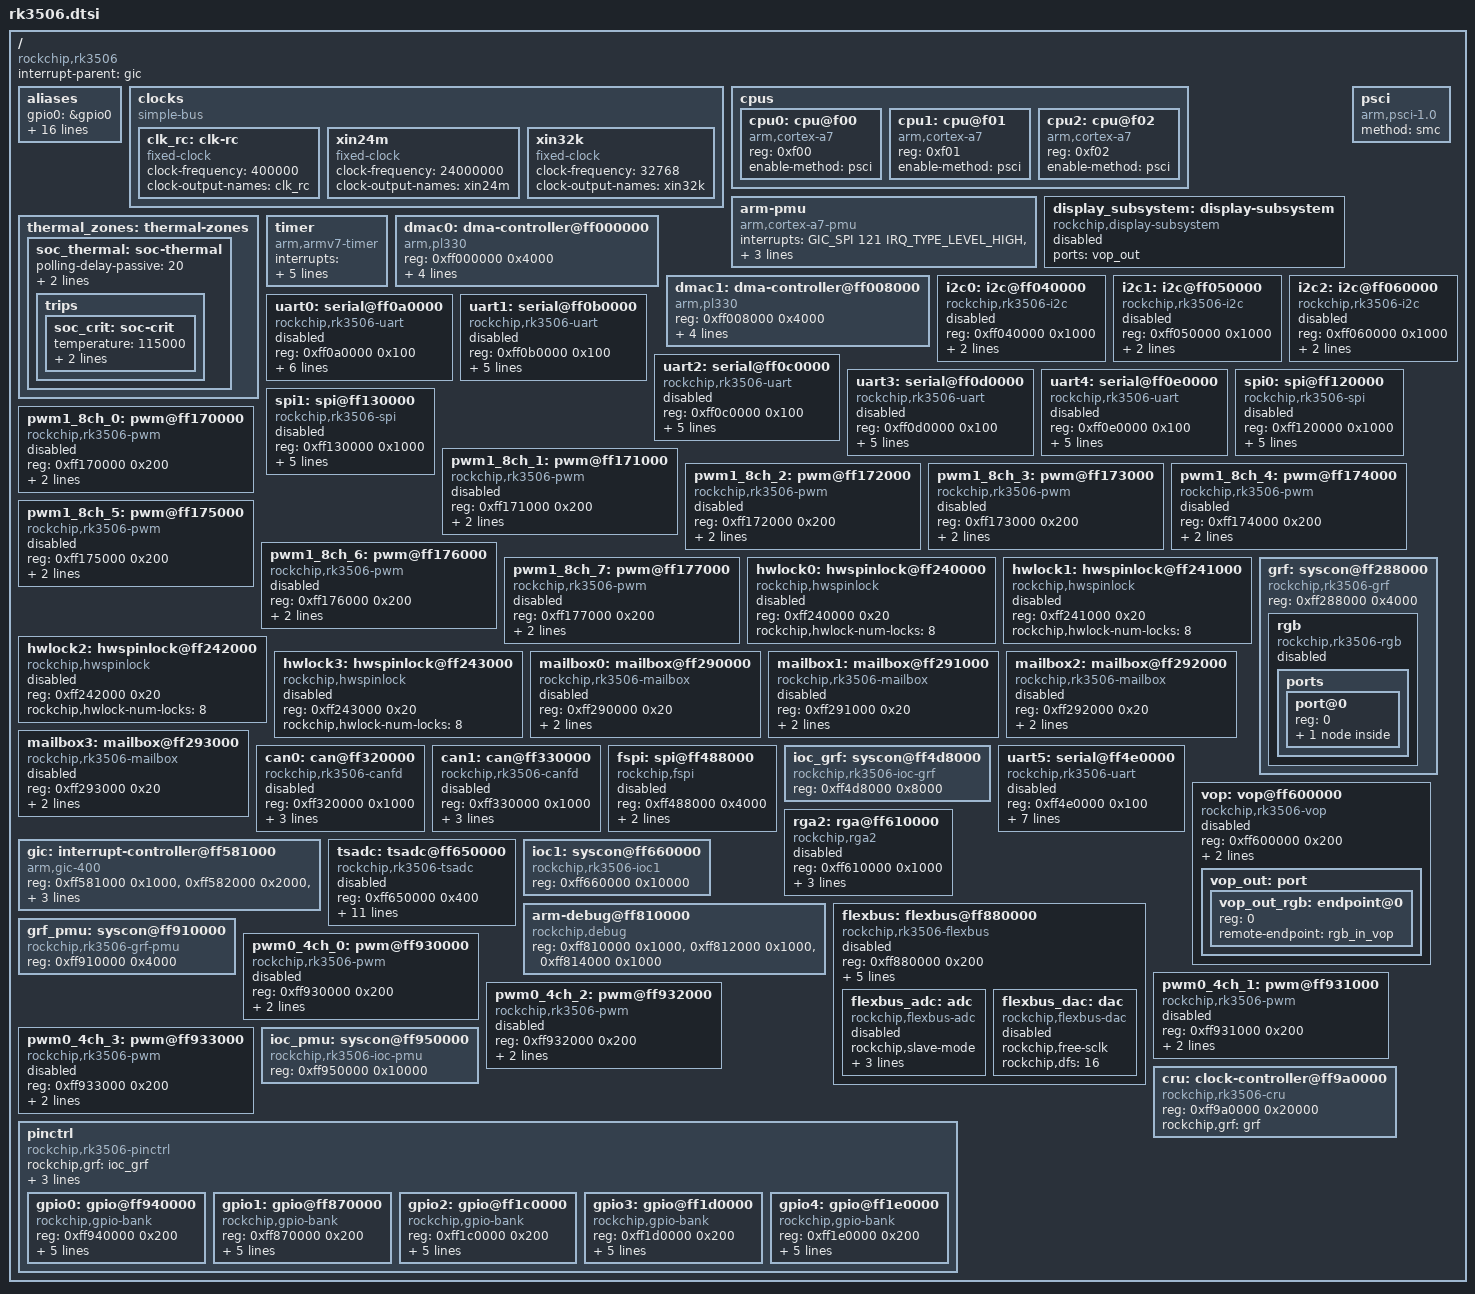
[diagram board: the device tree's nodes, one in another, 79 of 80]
// SPDX-License-Identifier: (GPL-2.0+ OR MIT)
/*
 * Copyright (c) 2023 Rockchip Electronics Co., Ltd.
 */

#include <dt-bindings/clock/rockchip,rk3506-cru.h>
#include <dt-bindings/interrupt-controller/irq.h>
#include <dt-bindings/interrupt-controller/arm-gic.h>
#include <dt-bindings/pinctrl/rockchip.h>

/ {
	#address-cells = <1>;
	#size-cells = <1>;

	compatible = "rockchip,rk3506";

	interrupt-parent = <&gic>;

	aliases {
		gpio0 = &gpio0;
		gpio1 = &gpio1;
		gpio2 = &gpio2;
		gpio3 = &gpio3;
		gpio4 = &gpio4;
		i2c0 = &i2c0;
		i2c1 = &i2c1;
		i2c2 = &i2c2;
		serial0 = &uart0;
		serial1 = &uart1;
		serial2 = &uart2;
		serial3 = &uart3;
		serial4 = &uart4;
		serial5 = &uart5;
		spi0 = &spi0;
		spi1 = &spi1;
		spi2 = &fspi;
	};

	clocks {
		compatible = "simple-bus";

		clk_rc: clk-rc {
			compatible = "fixed-clock";
			#clock-cells = <0>;
			clock-frequency = <400000>;
			clock-output-names = "clk_rc";
		};

		xin24m: xin24m {
			compatible = "fixed-clock";
			#clock-cells = <0>;
			clock-frequency = <24000000>;
			clock-output-names = "xin24m";
		};

		xin32k: xin32k {
			compatible = "fixed-clock";
			#clock-cells = <0>;
			clock-frequency = <32768>;
			clock-output-names = "xin32k";
		};
	};

	cpus {
		#address-cells = <1>;
		#size-cells = <0>;

		cpu0: cpu@f00 {
			device_type = "cpu";
			compatible = "arm,cortex-a7";
			reg = <0xf00>;
			enable-method = "psci";
		};

		cpu1: cpu@f01 {
			device_type = "cpu";
			compatible = "arm,cortex-a7";
			reg = <0xf01>;
			enable-method = "psci";
		};

		cpu2: cpu@f02 {
			device_type = "cpu";
			compatible = "arm,cortex-a7";
			reg = <0xf02>;
			enable-method = "psci";
		};
	};

	arm-pmu {
		compatible = "arm,cortex-a7-pmu";
		interrupts = <GIC_SPI 121 IRQ_TYPE_LEVEL_HIGH>,
			     <GIC_SPI 122 IRQ_TYPE_LEVEL_HIGH>,
			     <GIC_SPI 123 IRQ_TYPE_LEVEL_HIGH>;
		interrupt-affinity = <&cpu0>, <&cpu1>, <&cpu2>;
	};

	display_subsystem: display-subsystem {
		compatible = "rockchip,display-subsystem";
		ports = <&vop_out>;
		status = "disabled";
	};

	psci {
		compatible = "arm,psci-1.0";
		method = "smc";
	};

	thermal_zones: thermal-zones {
		soc_thermal: soc-thermal {
			polling-delay-passive = <20>; /* milliseconds */
			polling-delay = <1000>; /* milliseconds */
			thermal-sensors = <&tsadc 0>;
			trips {
				soc_crit: soc-crit {
					/* millicelsius */
					temperature = <115000>;
					/* millicelsius */
					hysteresis = <2000>;
					type = "critical";
				};
			};
		};
	};

	timer {
		compatible = "arm,armv7-timer";
		interrupts = <GIC_PPI 13 (GIC_CPU_MASK_SIMPLE(3) | IRQ_TYPE_LEVEL_HIGH)>,
			     <GIC_PPI 14 (GIC_CPU_MASK_SIMPLE(3) | IRQ_TYPE_LEVEL_HIGH)>,
			     <GIC_PPI 11 (GIC_CPU_MASK_SIMPLE(3) | IRQ_TYPE_LEVEL_HIGH)>,
			     <GIC_PPI 10 (GIC_CPU_MASK_SIMPLE(3) | IRQ_TYPE_LEVEL_HIGH)>;
		clock-frequency = <24000000>;
	};

	dmac0: dma-controller@ff000000 {
		compatible = "arm,pl330", "arm,primecell";
		reg = <0xff000000 0x4000>;
		interrupts = <GIC_SPI 116 IRQ_TYPE_LEVEL_HIGH>,
			     <GIC_SPI 117 IRQ_TYPE_LEVEL_HIGH>;
		clocks = <&cru ACLK_DMAC0>;
		clock-names = "apb_pclk";
		#dma-cells = <1>;
		arm,pl330-periph-burst;
	};

	dmac1: dma-controller@ff008000 {
		compatible = "arm,pl330", "arm,primecell";
		reg = <0xff008000 0x4000>;
		interrupts = <GIC_SPI 118 IRQ_TYPE_LEVEL_HIGH>,
			     <GIC_SPI 119 IRQ_TYPE_LEVEL_HIGH>;
		clocks = <&cru ACLK_DMAC1>;
		clock-names = "apb_pclk";
		#dma-cells = <1>;
		arm,pl330-periph-burst;
	};

	i2c0: i2c@ff040000 {
		compatible = "rockchip,rk3506-i2c", "rockchip,rk3399-i2c";
		reg = <0xff040000 0x1000>;
		interrupts = <GIC_SPI 40 IRQ_TYPE_LEVEL_HIGH>;
		#address-cells = <1>;
		#size-cells = <0>;
		clocks = <&cru CLK_I2C0>, <&cru PCLK_I2C0>;
		clock-names = "i2c", "pclk";
		status = "disabled";
	};

	i2c1: i2c@ff050000 {
		compatible = "rockchip,rk3506-i2c", "rockchip,rk3399-i2c";
		reg = <0xff050000 0x1000>;
		interrupts = <GIC_SPI 41 IRQ_TYPE_LEVEL_HIGH>;
		#address-cells = <1>;
		#size-cells = <0>;
		clocks = <&cru CLK_I2C1>, <&cru PCLK_I2C1>;
		clock-names = "i2c", "pclk";
		status = "disabled";
	};

	i2c2: i2c@ff060000 {
		compatible = "rockchip,rk3506-i2c", "rockchip,rk3399-i2c";
		reg = <0xff060000 0x1000>;
		interrupts = <GIC_SPI 42 IRQ_TYPE_LEVEL_HIGH>;
		#address-cells = <1>;
		#size-cells = <0>;
		clocks = <&cru CLK_I2C2>, <&cru PCLK_I2C2>;
		clock-names = "i2c", "pclk";
		status = "disabled";
	};

	uart0: serial@ff0a0000 {
		compatible = "rockchip,rk3506-uart", "snps,dw-apb-uart";
		reg = <0xff0a0000 0x100>;
		interrupts = <GIC_SPI 34 IRQ_TYPE_LEVEL_HIGH>;
		reg-shift = <2>;
		reg-io-width = <4>;
		dmas = <&dmac0 4>, <&dmac0 5>;
		clocks = <&cru SCLK_UART0>, <&cru PCLK_UART0>;
		clock-names = "baudclk", "apb_pclk";
		pinctrl-names = "default";
		pinctrl-0 = <&uart0_xfer_pins>;
		status = "disabled";
	};

	uart1: serial@ff0b0000 {
		compatible = "rockchip,rk3506-uart", "snps,dw-apb-uart";
		reg = <0xff0b0000 0x100>;
		interrupts = <GIC_SPI 35 IRQ_TYPE_LEVEL_HIGH>;
		reg-shift = <2>;
		reg-io-width = <4>;
		dmas = <&dmac0 6>, <&dmac0 7>;
		clocks = <&cru SCLK_UART1>, <&cru PCLK_UART1>;
		clock-names = "baudclk", "apb_pclk";
		status = "disabled";
	};

	uart2: serial@ff0c0000 {
		compatible = "rockchip,rk3506-uart", "snps,dw-apb-uart";
		reg = <0xff0c0000 0x100>;
		interrupts = <GIC_SPI 36 IRQ_TYPE_LEVEL_HIGH>;
		reg-shift = <2>;
		reg-io-width = <4>;
		dmas = <&dmac0 8>, <&dmac0 9>;
		clocks = <&cru SCLK_UART2>, <&cru PCLK_UART2>;
		clock-names = "baudclk", "apb_pclk";
		status = "disabled";
	};

	uart3: serial@ff0d0000 {
		compatible = "rockchip,rk3506-uart", "snps,dw-apb-uart";
		reg = <0xff0d0000 0x100>;
		interrupts = <GIC_SPI 37 IRQ_TYPE_LEVEL_HIGH>;
		reg-shift = <2>;
		reg-io-width = <4>;
		dmas = <&dmac0 10>, <&dmac0 11>;
		clocks = <&cru SCLK_UART3>, <&cru PCLK_UART3>;
		clock-names = "baudclk", "apb_pclk";
		status = "disabled";
	};

	uart4: serial@ff0e0000 {
		compatible = "rockchip,rk3506-uart", "snps,dw-apb-uart";
		reg = <0xff0e0000 0x100>;
		interrupts = <GIC_SPI 38 IRQ_TYPE_LEVEL_HIGH>;
		reg-shift = <2>;
		reg-io-width = <4>;
		dmas = <&dmac1 12>, <&dmac1 13>;
		clocks = <&cru SCLK_UART4>, <&cru PCLK_UART4>;
		clock-names = "baudclk", "apb_pclk";
		status = "disabled";
	};

	spi0: spi@ff120000 {
		compatible = "rockchip,rk3506-spi", "rockchip,rk3066-spi";
		reg = <0xff120000 0x1000>;
		interrupts = <GIC_SPI 43 IRQ_TYPE_LEVEL_HIGH>;
		#address-cells = <1>;
		#size-cells = <0>;
		clocks = <&cru CLK_SPI0>, <&cru PCLK_SPI0>;
		clock-names = "spiclk", "apb_pclk";
		dmas = <&dmac0 0>, <&dmac0 1>;
		dma-names = "tx", "rx";
		pinctrl-names = "default";
		pinctrl-0 = <&spi0_csn0_pins &spi0_csn1_pins &spi0_clk_pins>;
		status = "disabled";
	};

	spi1: spi@ff130000 {
		compatible = "rockchip,rk3506-spi", "rockchip,rk3066-spi";
		reg = <0xff130000 0x1000>;
		interrupts = <GIC_SPI 44 IRQ_TYPE_LEVEL_HIGH>;
		#address-cells = <1>;
		#size-cells = <0>;
		clocks = <&cru CLK_SPI1>, <&cru PCLK_SPI1>;
		clock-names = "spiclk", "apb_pclk";
		dmas = <&dmac0 2>, <&dmac0 3>;
		dma-names = "tx", "rx";
		pinctrl-names = "default";
		pinctrl-0 = <&spi1_csn0_pins &spi1_csn1_pins &spi1_clk_pins>;
		status = "disabled";
	};

	pwm1_8ch_0: pwm@ff170000 {
		compatible = "rockchip,rk3506-pwm", "rockchip,rk3576-pwm";
		reg = <0xff170000 0x200>;
		interrupts = <GIC_SPI 26 IRQ_TYPE_LEVEL_HIGH>;
		clocks = <&cru CLK_PWM1>, <&cru PCLK_PWM1>;
		clock-names = "pwm", "pclk";
		#pwm-cells = <3>;
		status = "disabled";
	};

	pwm1_8ch_1: pwm@ff171000 {
		compatible = "rockchip,rk3506-pwm", "rockchip,rk3576-pwm";
		reg = <0xff171000 0x200>;
		interrupts = <GIC_SPI 27 IRQ_TYPE_LEVEL_HIGH>;
		clocks = <&cru CLK_PWM1>, <&cru PCLK_PWM1>;
		clock-names = "pwm", "pclk";
		#pwm-cells = <3>;
		status = "disabled";
	};

	pwm1_8ch_2: pwm@ff172000 {
		compatible = "rockchip,rk3506-pwm", "rockchip,rk3576-pwm";
		reg = <0xff172000 0x200>;
		interrupts = <GIC_SPI 28 IRQ_TYPE_LEVEL_HIGH>;
		clocks = <&cru CLK_PWM1>, <&cru PCLK_PWM1>;
		clock-names = "pwm", "pclk";
		#pwm-cells = <3>;
		status = "disabled";
	};

	pwm1_8ch_3: pwm@ff173000 {
		compatible = "rockchip,rk3506-pwm", "rockchip,rk3576-pwm";
		reg = <0xff173000 0x200>;
		interrupts = <GIC_SPI 29 IRQ_TYPE_LEVEL_HIGH>;
		clocks = <&cru CLK_PWM1>, <&cru PCLK_PWM1>;
		clock-names = "pwm", "pclk";
		#pwm-cells = <3>;
		status = "disabled";
	};

	pwm1_8ch_4: pwm@ff174000 {
		compatible = "rockchip,rk3506-pwm", "rockchip,rk3576-pwm";
		reg = <0xff174000 0x200>;
		interrupts = <GIC_SPI 30 IRQ_TYPE_LEVEL_HIGH>;
		clocks = <&cru CLK_PWM1>, <&cru PCLK_PWM1>;
		clock-names = "pwm", "pclk";
		#pwm-cells = <3>;
		status = "disabled";
	};

	pwm1_8ch_5: pwm@ff175000 {
		compatible = "rockchip,rk3506-pwm", "rockchip,rk3576-pwm";
		reg = <0xff175000 0x200>;
		interrupts = <GIC_SPI 31 IRQ_TYPE_LEVEL_HIGH>;
		clocks = <&cru CLK_PWM1>, <&cru PCLK_PWM1>;
		clock-names = "pwm", "pclk";
		#pwm-cells = <3>;
		status = "disabled";
	};

	pwm1_8ch_6: pwm@ff176000 {
		compatible = "rockchip,rk3506-pwm", "rockchip,rk3576-pwm";
		reg = <0xff176000 0x200>;
		interrupts = <GIC_SPI 32 IRQ_TYPE_LEVEL_HIGH>;
		clocks = <&cru CLK_PWM1>, <&cru PCLK_PWM1>;
		clock-names = "pwm", "pclk";
		#pwm-cells = <3>;
		status = "disabled";
	};

	pwm1_8ch_7: pwm@ff177000 {
		compatible = "rockchip,rk3506-pwm", "rockchip,rk3576-pwm";
		reg = <0xff177000 0x200>;
		interrupts = <GIC_SPI 33 IRQ_TYPE_LEVEL_HIGH>;
		clocks = <&cru CLK_PWM1>, <&cru PCLK_PWM1>;
		clock-names = "pwm", "pclk";
		#pwm-cells = <3>;
		status = "disabled";
	};

	hwlock0: hwspinlock@ff240000 {
		compatible = "rockchip,hwspinlock";
		reg = <0xff240000 0x20>;
		#hwlock-cells = <1>;
		rockchip,hwlock-num-locks = <8>;
		status = "disabled";
	};

	hwlock1: hwspinlock@ff241000 {
		compatible = "rockchip,hwspinlock";
		reg = <0xff241000 0x20>;
		#hwlock-cells = <1>;
		rockchip,hwlock-num-locks = <8>;
		status = "disabled";
	};

	hwlock2: hwspinlock@ff242000 {
		compatible = "rockchip,hwspinlock";
		reg = <0xff242000 0x20>;
		#hwlock-cells = <1>;
		rockchip,hwlock-num-locks = <8>;
		status = "disabled";
	};

	hwlock3: hwspinlock@ff243000 {
		compatible = "rockchip,hwspinlock";
		reg = <0xff243000 0x20>;
		#hwlock-cells = <1>;
		rockchip,hwlock-num-locks = <8>;
		status = "disabled";
	};

	grf: syscon@ff288000 {
		compatible = "rockchip,rk3506-grf", "syscon", "simple-mfd";
		reg = <0xff288000 0x4000>;

		rgb: rgb {
			compatible = "rockchip,rk3506-rgb";
			status = "disabled";

			ports {
				#address-cells = <1>;
				#size-cells = <0>;

				port@0 {
					reg = <0>;
					#address-cells = <1>;
					#size-cells = <0>;

					rgb_in_vop: endpoint@0 {
						reg = <0>;
						remote-endpoint = <&vop_out_rgb>;
					};
				};
			};
		};
	};

	mailbox0: mailbox@ff290000 {
		compatible = "rockchip,rk3506-mailbox", "rockchip,rk3576-mailbox";
		reg = <0xff290000 0x20>;
		interrupts = <GIC_SPI 138 IRQ_TYPE_LEVEL_HIGH>;
		clocks = <&cru PCLK_MAILBOX>;
		clock-names = "pclk_mailbox";
		#mbox-cells = <1>;
		status = "disabled";
	};

	mailbox1: mailbox@ff291000 {
		compatible = "rockchip,rk3506-mailbox", "rockchip,rk3576-mailbox";
		reg = <0xff291000 0x20>;
		interrupts = <GIC_SPI 139 IRQ_TYPE_LEVEL_HIGH>;
		clocks = <&cru PCLK_MAILBOX>;
		clock-names = "pclk_mailbox";
		#mbox-cells = <1>;
		status = "disabled";
	};

	mailbox2: mailbox@ff292000 {
		compatible = "rockchip,rk3506-mailbox", "rockchip,rk3576-mailbox";
		reg = <0xff292000 0x20>;
		interrupts = <GIC_SPI 140 IRQ_TYPE_LEVEL_HIGH>;
		clocks = <&cru PCLK_MAILBOX>;
		clock-names = "pclk_mailbox";
		#mbox-cells = <1>;
		status = "disabled";
	};

	mailbox3: mailbox@ff293000 {
		compatible = "rockchip,rk3506-mailbox", "rockchip,rk3576-mailbox";
		reg = <0xff293000 0x20>;
		interrupts = <GIC_SPI 141 IRQ_TYPE_LEVEL_HIGH>;
		clocks = <&cru PCLK_MAILBOX>;
		clock-names = "pclk_mailbox";
		#mbox-cells = <1>;
		status = "disabled";
	};

	can0: can@ff320000 {
		compatible = "rockchip,rk3506-canfd", "rockchip,rk3576-canfd";
		reg = <0xff320000 0x1000>;
		interrupts = <GIC_SPI 45 IRQ_TYPE_LEVEL_HIGH>;
		clocks = <&cru CLK_CAN0>, <&cru HCLK_CAN0>;
		clock-names = "baudclk", "apb_pclk";
		resets = <&cru SRST_CAN0>, <&cru SRST_H_CAN0>;
		reset-names = "can", "can-apb";
		status = "disabled";
	};

	can1: can@ff330000 {
		compatible = "rockchip,rk3506-canfd", "rockchip,rk3576-canfd";
		reg = <0xff330000 0x1000>;
		interrupts = <GIC_SPI 46 IRQ_TYPE_LEVEL_HIGH>;
		clocks = <&cru CLK_CAN1>, <&cru HCLK_CAN1>;
		clock-names = "baudclk", "apb_pclk";
		resets = <&cru SRST_CAN1>, <&cru SRST_H_CAN1>;
		reset-names = "can", "can-apb";
		status = "disabled";
	};

	fspi: spi@ff488000 {
		compatible = "rockchip,fspi";
		reg = <0xff488000 0x4000>;
		interrupts = <GIC_SPI 85 IRQ_TYPE_LEVEL_HIGH>;
		clocks = <&cru SCLK_FSPI>, <&cru HCLK_FSPI>;
		clock-names = "clk_sfc", "hclk_sfc";
		#address-cells = <1>;
		#size-cells = <0>;
		status = "disabled";
	};

	ioc_grf: syscon@ff4d8000 {
		compatible = "rockchip,rk3506-ioc-grf", "syscon";
		reg = <0xff4d8000 0x8000>;
	};

	uart5: serial@ff4e0000 {
		compatible = "rockchip,rk3506-uart", "snps,dw-apb-uart";
		reg = <0xff4e0000 0x100>;
		interrupts = <GIC_SPI 39 IRQ_TYPE_LEVEL_HIGH>;
		reg-shift = <2>;
		reg-io-width = <4>;
		dmas = <&dmac1 14>, <&dmac1 15>;
		clocks = <&cru SCLK_UART5>, <&cru PCLK_UART5>;
		clock-names = "baudclk", "apb_pclk";
		pinctrl-names = "default";
		pinctrl-0 = <&uart5m0_xfer_pins &uart5m0_ctsn_pins &uart5m0_rtsn_pins>;
		status = "disabled";
	};

	gic: interrupt-controller@ff581000 {
		compatible = "arm,gic-400";
		reg = <0xff581000 0x1000>,
		      <0xff582000 0x2000>,
		      <0xff584000 0x2000>,
		      <0xff586000 0x2000>;
		interrupts = <GIC_PPI 9 IRQ_TYPE_LEVEL_HIGH>;
		#interrupt-cells = <3>;
		interrupt-controller;
		#address-cells = <0>;
	};

	vop: vop@ff600000 {
		compatible = "rockchip,rk3506-vop";
		reg = <0xff600000 0x200>;
		reg-names = "regs";
		rockchip,grf = <&grf>;
		interrupts = <GIC_SPI 59 IRQ_TYPE_LEVEL_HIGH>;
		status = "disabled";

		vop_out: port {
			#address-cells = <1>;
			#size-cells = <0>;

			vop_out_rgb: endpoint@0 {
				reg = <0>;
				remote-endpoint = <&rgb_in_vop>;
			};
		};
	};

	rga2: rga@ff610000 {
		compatible = "rockchip,rga2";
		reg = <0xff610000 0x1000>;
		interrupts = <GIC_SPI 61 IRQ_TYPE_LEVEL_HIGH>;
		interrupt-names = "rga2_irq";
		clocks = <&cru ACLK_RGA>, <&cru HCLK_RGA>, <&cru CLK_CORE_RGA>;
		clock-names = "aclk_rga", "hclk_rga", "clk_rga";
		status = "disabled";
	};

	tsadc: tsadc@ff650000 {
		compatible = "rockchip,rk3506-tsadc";
		reg = <0xff650000 0x400>;
		interrupts = <GIC_SPI 58 IRQ_TYPE_LEVEL_HIGH>;
		clocks = <&cru CLK_TSADC>, <&cru PCLK_TSADC>, <&cru CLK_TSADC_TSEN>;
		clock-names = "tsadc", "apb_pclk", "tsen";
		assigned-clocks = <&cru CLK_TSADC>, <&cru CLK_TSADC_TSEN>;
		assigned-clock-rates = <1000000>, <12000000>;
		resets = <&cru SRST_TSADC>, <&cru SRST_P_TSADC>;
		reset-names = "tsadc", "tsadc-apb";
		#thermal-sensor-cells = <1>;
		rockchip,grf = <&grf>;
		rockchip,hw-tshut-temp = <120000>;
		rockchip,hw-tshut-mode = <0>; /* tshut mode 0:CRU 1:GPIO */
		rockchip,hw-tshut-polarity = <0>; /* tshut polarity 0:LOW 1:HIGH */
		status = "disabled";
	};

	ioc1: syscon@ff660000 {
		compatible = "rockchip,rk3506-ioc1", "syscon";
		reg = <0xff660000 0x10000>;
	};

	arm-debug@ff810000 {
		compatible = "rockchip,debug";
		reg = <0xff810000 0x1000>,
		      <0xff812000 0x1000>,
		      <0xff814000 0x1000>;
	};

	flexbus: flexbus@ff880000 {
		compatible = "rockchip,rk3506-flexbus";
		reg = <0xff880000 0x200>;
		interrupts = <GIC_SPI 127 IRQ_TYPE_LEVEL_HIGH>;
		clocks = <&cru CLK_FLEXBUS_TX>, <&cru CLK_FLEXBUS_RX>,
			 <&cru ACLK_FLEXBUS>, <&cru HCLK_FLEXBUS>;
		clock-names = "tx_clk_flexbus", "rx_clk_flexbus",
			      "aclk_flexbus", "hclk_flexbus";
		rockchip,grf = <&grf>;
		status = "disabled";

		flexbus_adc: adc {
			compatible = "rockchip,flexbus-adc";
			#io-channel-cells = <0>;
			rockchip,slave-mode;
			rockchip,free-sclk;
			rockchip,auto-pad;
			rockchip,dfs = <16>;
			status = "disabled";
		};

		flexbus_dac: dac {
			compatible = "rockchip,flexbus-dac";
			#io-channel-cells = <0>;
			rockchip,free-sclk;
			rockchip,dfs = <16>;
			status = "disabled";
		};
	};

	grf_pmu: syscon@ff910000 {
		compatible = "rockchip,rk3506-grf-pmu", "syscon";
		reg = <0xff910000 0x4000>;
	};

	pwm0_4ch_0: pwm@ff930000 {
		compatible = "rockchip,rk3506-pwm", "rockchip,rk3576-pwm";
		reg = <0xff930000 0x200>;
		interrupts = <GIC_SPI 22 IRQ_TYPE_LEVEL_HIGH>;
		clocks = <&cru CLK_PWM0>, <&cru PCLK_PWM0>;
		clock-names = "pwm", "pclk";
		#pwm-cells = <3>;
		status = "disabled";
	};

	pwm0_4ch_1: pwm@ff931000 {
		compatible = "rockchip,rk3506-pwm", "rockchip,rk3576-pwm";
		reg = <0xff931000 0x200>;
		interrupts = <GIC_SPI 23 IRQ_TYPE_LEVEL_HIGH>;
		clocks = <&cru CLK_PWM0>, <&cru PCLK_PWM0>;
		clock-names = "pwm", "pclk";
		#pwm-cells = <3>;
		status = "disabled";
	};

	pwm0_4ch_2: pwm@ff932000 {
		compatible = "rockchip,rk3506-pwm", "rockchip,rk3576-pwm";
		reg = <0xff932000 0x200>;
		interrupts = <GIC_SPI 24 IRQ_TYPE_LEVEL_HIGH>;
		clocks = <&cru CLK_PWM0>, <&cru PCLK_PWM0>;
		clock-names = "pwm", "pclk";
		#pwm-cells = <3>;
		status = "disabled";
	};

	pwm0_4ch_3: pwm@ff933000 {
		compatible = "rockchip,rk3506-pwm", "rockchip,rk3576-pwm";
		reg = <0xff933000 0x200>;
		interrupts = <GIC_SPI 25 IRQ_TYPE_LEVEL_HIGH>;
		clocks = <&cru CLK_PWM0>, <&cru PCLK_PWM0>;
		clock-names = "pwm", "pclk";
		#pwm-cells = <3>;
		status = "disabled";
	};

	ioc_pmu: syscon@ff950000 {
		compatible = "rockchip,rk3506-ioc-pmu", "syscon";
		reg = <0xff950000 0x10000>;
	};

	cru: clock-controller@ff9a0000 {
		compatible = "rockchip,rk3506-cru";
		reg = <0xff9a0000 0x20000>;
		rockchip,grf = <&grf>;
		#clock-cells = <1>;
		#reset-cells = <1>;
	};

	pinctrl: pinctrl {
		compatible = "rockchip,rk3506-pinctrl";
		rockchip,grf = <&ioc_grf>;
		rockchip,ioc1 = <&ioc1>;
		rockchip,pmu = <&ioc_pmu>;
		rockchip,rmio = <&grf_pmu>;
		#address-cells = <1>;
		#size-cells = <1>;
		ranges;

		gpio0: gpio@ff940000 {
			compatible = "rockchip,gpio-bank";
			reg = <0xff940000 0x200>;
			interrupts = <GIC_SPI 0 IRQ_TYPE_LEVEL_HIGH>;
			clocks = <&cru PCLK_GPIO0>, <&cru DBCLK_GPIO0>;

			gpio-controller;
			#gpio-cells = <2>;
			gpio-ranges = <&pinctrl 0 0 32>;
			interrupt-controller;
			#interrupt-cells = <2>;
		};

		gpio1: gpio@ff870000 {
			compatible = "rockchip,gpio-bank";
			reg = <0xff870000 0x200>;
			interrupts = <GIC_SPI 4 IRQ_TYPE_LEVEL_HIGH>;
			clocks = <&cru PCLK_GPIO1>, <&cru DBCLK_GPIO1>;

			gpio-controller;
			#gpio-cells = <2>;
			gpio-ranges = <&pinctrl 0 32 32>;
			interrupt-controller;
			#interrupt-cells = <2>;
		};

		gpio2: gpio@ff1c0000 {
			compatible = "rockchip,gpio-bank";
			reg = <0xff1c0000 0x200>;
			interrupts = <GIC_SPI 8 IRQ_TYPE_LEVEL_HIGH>;
			clocks = <&cru PCLK_GPIO2>, <&cru DBCLK_GPIO2>;

			gpio-controller;
			#gpio-cells = <2>;
			gpio-ranges = <&pinctrl 0 64 32>;
			interrupt-controller;
			#interrupt-cells = <2>;
		};

		gpio3: gpio@ff1d0000 {
			compatible = "rockchip,gpio-bank";
			reg = <0xff1d0000 0x200>;
			interrupts = <GIC_SPI 12 IRQ_TYPE_LEVEL_HIGH>;
			clocks = <&cru PCLK_GPIO3>, <&cru DBCLK_GPIO3>;

			gpio-controller;
			#gpio-cells = <2>;
			gpio-ranges = <&pinctrl 0 96 32>;
			interrupt-controller;
			#interrupt-cells = <2>;
		};

		gpio4: gpio@ff1e0000 {
			compatible = "rockchip,gpio-bank";
			reg = <0xff1e0000 0x200>;
			interrupts = <GIC_SPI 16 IRQ_TYPE_LEVEL_HIGH>;
			clocks = <&cru PCLK_GPIO4>, <&cru DBCLK_GPIO4>;

			gpio-controller;
			#gpio-cells = <2>;
			gpio-ranges = <&pinctrl 0 128 32>;
			interrupt-controller;
			#interrupt-cells = <2>;
		};
	};
};

#include "rk3506-pinctrl.dtsi"
#include "rk3506-pinctrl-rmio.dtsi"
